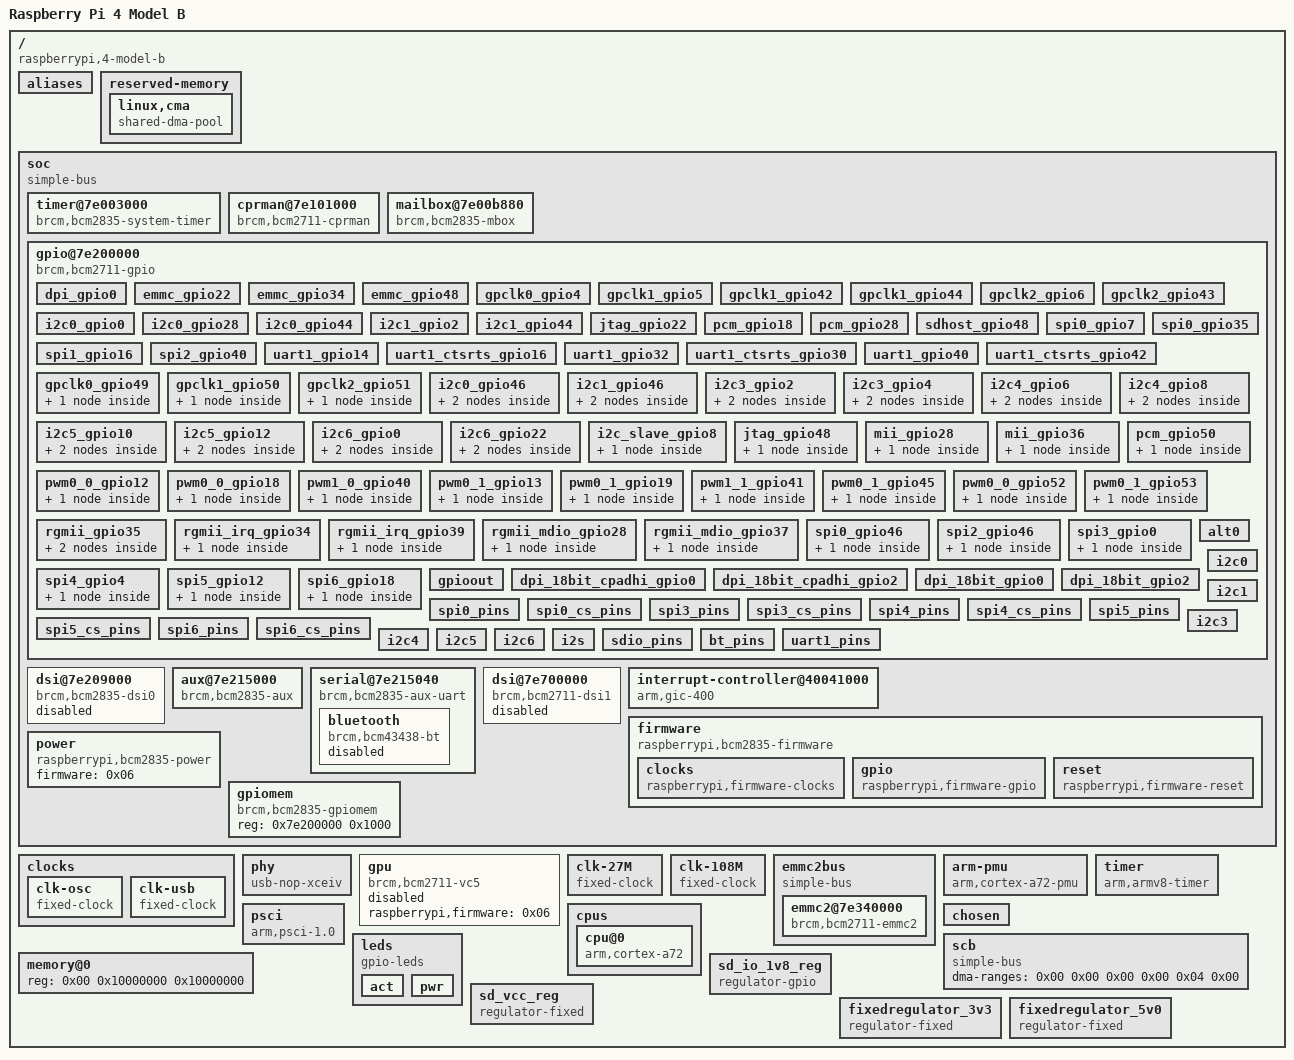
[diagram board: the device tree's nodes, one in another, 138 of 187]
/dts-v1/;

/memreserve/	0x0000000000000000 0x0000000000001000;
/ {
	compatible = "raspberrypi,4-model-b\0brcm,bcm2711";
	model = "Raspberry Pi 4 Model B";
	#address-cells = <0x02>;
	#size-cells = <0x01>;
	interrupt-parent = <0x01>;

	aliases {
		serial0 = "/soc/serial@7e215040";
		emmc2bus = "/emmc2bus";
		aux = "/soc/aux@7e215000";
		soc = "/soc";
		gpio = "/soc/gpio@7e200000";
		uart1 = "/soc/serial@7e215040";
		leds = "/leds";
	};

	reserved-memory {
		#address-cells = <0x02>;
		#size-cells = <0x01>;
		ranges;
		phandle = <0x41>;

		linux,cma {
			compatible = "shared-dma-pool";
			size = <0x1000000>;
			reusable;
			linux,cma-default;
			alloc-ranges = <0x00 0x10000000 0x30000000>;
			phandle = <0x42>;
		};
	};

	soc {
		compatible = "simple-bus";
		#address-cells = <0x01>;
		#size-cells = <0x01>;
		ranges = <0x7e000000 0x00 0xfe000000 0x1800000 0x7c000000 0x00 0xfc000000 0x2000000 0x40000000 0x00 0xff800000 0x800000>;
		dma-ranges = <0xd0000000 0x00 0x10000000 0x10000000>;
		phandle = <0x45>;

		timer@7e003000 {
			compatible = "brcm,bcm2835-system-timer";
			reg = <0x7e003000 0x1000>;
			interrupts = <0x00 0x40 0x04 0x00 0x41 0x04 0x00 0x42 0x04 0x00 0x43 0x04>;
			clock-frequency = <0xf4240>;
			phandle = <0x46>;
		};

		cprman@7e101000 {
			compatible = "brcm,bcm2711-cprman";
			#clock-cells = <0x01>;
			reg = <0x7e101000 0x2000>;
			clocks = <0x03 0x04 0x00 0x04 0x01 0x04 0x02 0x05 0x00 0x05 0x01 0x05 0x02>;
			firmware = <0x06>;
			phandle = <0x07>;
		};

		mailbox@7e00b880 {
			compatible = "brcm,bcm2835-mbox";
			reg = <0x7e00b880 0x40>;
			interrupts = <0x00 0x21 0x04>;
			#mbox-cells = <0x00>;
			phandle = <0x22>;
		};

		gpio@7e200000 {
			compatible = "brcm,bcm2711-gpio";
			reg = <0x7e200000 0xb4>;
			interrupts = <0x00 0x71 0x04 0x00 0x72 0x04>;
			gpio-controller;
			#gpio-cells = <0x02>;
			interrupt-controller;
			#interrupt-cells = <0x02>;
			pinctrl-names = "default";
			gpio-line-names = "ID_SDA\0ID_SCL\0SDA1\0SCL1\0GPIO_GCLK\0GPIO5\0GPIO6\0SPI_CE1_N\0SPI_CE0_N\0SPI_MISO\0SPI_MOSI\0SPI_SCLK\0GPIO12\0GPIO13\0TXD1\0RXD1\0GPIO16\0GPIO17\0GPIO18\0GPIO19\0GPIO20\0GPIO21\0GPIO22\0GPIO23\0GPIO24\0GPIO25\0GPIO26\0GPIO27\0RGMII_MDIO\0RGMIO_MDC\0CTS0\0RTS0\0TXD0\0RXD0\0SD1_CLK\0SD1_CMD\0SD1_DATA0\0SD1_DATA1\0SD1_DATA2\0SD1_DATA3\0PWM0_MISO\0PWM1_MOSI\0STATUS_LED_G_CLK\0SPIFLASH_CE_N\0SDA0\0SCL0\0RGMII_RXCLK\0RGMII_RXCTL\0RGMII_RXD0\0RGMII_RXD1\0RGMII_RXD2\0RGMII_RXD3\0RGMII_TXCLK\0RGMII_TXCTL\0RGMII_TXD0\0RGMII_TXD1\0RGMII_TXD2\0RGMII_TXD3";
			phandle = <0x0f>;

			dpi_gpio0 {
				brcm,pins = <0x00 0x01 0x02 0x03 0x04 0x05 0x06 0x07 0x08 0x09 0x0a 0x0b 0x0c 0x0d 0x0e 0x0f 0x10 0x11 0x12 0x13 0x14 0x15 0x16 0x17 0x18 0x19 0x1a 0x1b>;
				brcm,function = <0x06>;
				phandle = <0x48>;
			};

			emmc_gpio22 {
				brcm,pins = <0x16 0x17 0x18 0x19 0x1a 0x1b>;
				brcm,function = <0x07>;
				phandle = <0x49>;
			};

			emmc_gpio34 {
				brcm,pins = <0x22 0x23 0x24 0x25 0x26 0x27>;
				brcm,function = <0x07>;
				brcm,pull = <0x00 0x02 0x02 0x02 0x02 0x02>;
				phandle = <0x4a>;
			};

			emmc_gpio48 {
				brcm,pins = <0x30 0x31 0x32 0x33 0x34 0x35>;
				brcm,function = <0x07>;
				phandle = <0x24>;
			};

			gpclk0_gpio4 {
				brcm,pins = <0x04>;
				brcm,function = <0x04>;
				phandle = <0x4b>;
			};

			gpclk1_gpio5 {
				brcm,pins = <0x05>;
				brcm,function = <0x04>;
				phandle = <0x4c>;
			};

			gpclk1_gpio42 {
				brcm,pins = <0x2a>;
				brcm,function = <0x04>;
				phandle = <0x4d>;
			};

			gpclk1_gpio44 {
				brcm,pins = <0x2c>;
				brcm,function = <0x04>;
				phandle = <0x4e>;
			};

			gpclk2_gpio6 {
				brcm,pins = <0x06>;
				brcm,function = <0x04>;
				phandle = <0x4f>;
			};

			gpclk2_gpio43 {
				brcm,pins = <0x2b>;
				brcm,function = <0x04>;
				brcm,pull = <0x00>;
				phandle = <0x50>;
			};

			i2c0_gpio0 {
				brcm,pins = <0x00 0x01>;
				brcm,function = <0x04>;
				phandle = <0x11>;
			};

			i2c0_gpio28 {
				brcm,pins = <0x1c 0x1d>;
				brcm,function = <0x04>;
				phandle = <0x51>;
			};

			i2c0_gpio44 {
				brcm,pins = <0x2c 0x2d>;
				brcm,function = <0x05>;
				phandle = <0x12>;
			};

			i2c1_gpio2 {
				brcm,pins = <0x02 0x03>;
				brcm,function = <0x04>;
				phandle = <0x52>;
			};

			i2c1_gpio44 {
				brcm,pins = <0x2c 0x2d>;
				brcm,function = <0x06>;
				phandle = <0x53>;
			};

			jtag_gpio22 {
				brcm,pins = <0x16 0x17 0x18 0x19 0x1a 0x1b>;
				brcm,function = <0x03>;
				phandle = <0x54>;
			};

			pcm_gpio18 {
				brcm,pins = <0x12 0x13 0x14 0x15>;
				brcm,function = <0x04>;
				phandle = <0x55>;
			};

			pcm_gpio28 {
				brcm,pins = <0x1c 0x1d 0x1e 0x1f>;
				brcm,function = <0x06>;
				phandle = <0x56>;
			};

			sdhost_gpio48 {
				brcm,pins = <0x30 0x31 0x32 0x33 0x34 0x35>;
				brcm,function = <0x04>;
				phandle = <0x57>;
			};

			spi0_gpio7 {
				brcm,pins = <0x07 0x08 0x09 0x0a 0x0b>;
				brcm,function = <0x04>;
				phandle = <0x58>;
			};

			spi0_gpio35 {
				brcm,pins = <0x23 0x24 0x25 0x26 0x27>;
				brcm,function = <0x04>;
				phandle = <0x59>;
			};

			spi1_gpio16 {
				brcm,pins = <0x10 0x11 0x12 0x13 0x14 0x15>;
				brcm,function = <0x03>;
				phandle = <0x5a>;
			};

			spi2_gpio40 {
				brcm,pins = <0x28 0x29 0x2a 0x2b 0x2c 0x2d>;
				brcm,function = <0x03>;
				phandle = <0x5b>;
			};

			uart1_gpio14 {
				brcm,pins = <0x0e 0x0f>;
				brcm,function = <0x02>;
				phandle = <0x62>;
			};

			uart1_ctsrts_gpio16 {
				brcm,pins = <0x10 0x11>;
				brcm,function = <0x02>;
				phandle = <0x63>;
			};

			uart1_gpio32 {
				brcm,pins = <0x20 0x21>;
				brcm,function = <0x02>;
				phandle = <0x64>;
			};

			uart1_ctsrts_gpio30 {
				brcm,pins = <0x1e 0x1f>;
				brcm,function = <0x02>;
				phandle = <0x65>;
			};

			uart1_gpio40 {
				brcm,pins = <0x28 0x29>;
				brcm,function = <0x02>;
				phandle = <0x66>;
			};

			uart1_ctsrts_gpio42 {
				brcm,pins = <0x2a 0x2b>;
				brcm,function = <0x02>;
				phandle = <0x67>;
			};

			gpclk0_gpio49 {
				phandle = <0x68>;

				pin-gpclk {
					pins = "gpio49";
					function = "alt1";
					bias-disable;
				};
			};

			gpclk1_gpio50 {
				phandle = <0x69>;

				pin-gpclk {
					pins = "gpio50";
					function = "alt1";
					bias-disable;
				};
			};

			gpclk2_gpio51 {
				phandle = <0x6a>;

				pin-gpclk {
					pins = "gpio51";
					function = "alt1";
					bias-disable;
				};
			};

			i2c0_gpio46 {
				phandle = <0x6b>;

				pin-sda {
					function = "alt0";
					pins = "gpio46";
					bias-pull-up;
				};

				pin-scl {
					function = "alt0";
					pins = "gpio47";
					bias-disable;
				};
			};

			i2c1_gpio46 {
				phandle = <0x6c>;

				pin-sda {
					function = "alt1";
					pins = "gpio46";
					bias-pull-up;
				};

				pin-scl {
					function = "alt1";
					pins = "gpio47";
					bias-disable;
				};
			};

			i2c3_gpio2 {
				phandle = <0x6d>;

				pin-sda {
					function = "alt5";
					pins = "gpio2";
					bias-pull-up;
				};

				pin-scl {
					function = "alt5";
					pins = "gpio3";
					bias-disable;
				};
			};

			i2c3_gpio4 {
				phandle = <0x6e>;

				pin-sda {
					function = "alt5";
					pins = "gpio4";
					bias-pull-up;
				};

				pin-scl {
					function = "alt5";
					pins = "gpio5";
					bias-disable;
				};
			};

			i2c4_gpio6 {
				phandle = <0x6f>;

				pin-sda {
					function = "alt5";
					pins = "gpio6";
					bias-pull-up;
				};

				pin-scl {
					function = "alt5";
					pins = "gpio7";
					bias-disable;
				};
			};

			i2c4_gpio8 {
				phandle = <0x70>;

				pin-sda {
					function = "alt5";
					pins = "gpio8";
					bias-pull-up;
				};

				pin-scl {
					function = "alt5";
					pins = "gpio9";
					bias-disable;
				};
			};

			i2c5_gpio10 {
				phandle = <0x71>;

				pin-sda {
					function = "alt5";
					pins = "gpio10";
					bias-pull-up;
				};

				pin-scl {
					function = "alt5";
					pins = "gpio11";
					bias-disable;
				};
			};

			i2c5_gpio12 {
				phandle = <0x72>;

				pin-sda {
					function = "alt5";
					pins = "gpio12";
					bias-pull-up;
				};

				pin-scl {
					function = "alt5";
					pins = "gpio13";
					bias-disable;
				};
			};

			i2c6_gpio0 {
				phandle = <0x73>;

				pin-sda {
					function = "alt5";
					pins = "gpio0";
					bias-pull-up;
				};

				pin-scl {
					function = "alt5";
					pins = "gpio1";
					bias-disable;
				};
			};

			i2c6_gpio22 {
				phandle = <0x74>;

				pin-sda {
					function = "alt5";
					pins = "gpio22";
					bias-pull-up;
				};

				pin-scl {
					function = "alt5";
					pins = "gpio23";
					bias-disable;
				};
			};

			i2c_slave_gpio8 {
				phandle = <0x75>;

				pins-i2c-slave {
					pins = "gpio8\0gpio9\0gpio10\0gpio11";
					function = "alt3";
				};
			};

			jtag_gpio48 {
				phandle = <0x76>;

				pins-jtag {
					pins = "gpio48\0gpio49\0gpio50\0gpio51\0gpio52\0gpio53";
					function = "alt4";
				};
			};

			mii_gpio28 {
				phandle = <0x77>;

				pins-mii {
					pins = "gpio28\0gpio29\0gpio30\0gpio31";
					function = "alt4";
				};
			};

			mii_gpio36 {
				phandle = <0x78>;

				pins-mii {
					pins = "gpio36\0gpio37\0gpio38\0gpio39";
					function = "alt5";
				};
			};

			pcm_gpio50 {
				phandle = <0x79>;

				pins-pcm {
					pins = "gpio50\0gpio51\0gpio52\0gpio53";
					function = "alt2";
				};
			};

			pwm0_0_gpio12 {
				phandle = <0x7a>;

				pin-pwm {
					pins = "gpio12";
					function = "alt0";
					bias-disable;
				};
			};

			pwm0_0_gpio18 {
				phandle = <0x7b>;

				pin-pwm {
					pins = "gpio18";
					function = "alt5";
					bias-disable;
				};
			};

			pwm1_0_gpio40 {
				phandle = <0x1a>;

				pin-pwm {
					pins = "gpio40";
					function = "alt0";
					bias-disable;
				};
			};

			pwm0_1_gpio13 {
				phandle = <0x7c>;

				pin-pwm {
					pins = "gpio13";
					function = "alt0";
					bias-disable;
				};
			};

			pwm0_1_gpio19 {
				phandle = <0x7d>;

				pin-pwm {
					pins = "gpio19";
					function = "alt5";
					bias-disable;
				};
			};

			pwm1_1_gpio41 {
				phandle = <0x1b>;

				pin-pwm {
					pins = "gpio41";
					function = "alt0";
					bias-disable;
				};
			};

			pwm0_1_gpio45 {
				phandle = <0x7e>;

				pin-pwm {
					pins = "gpio45";
					function = "alt0";
					bias-disable;
				};
			};

			pwm0_0_gpio52 {
				phandle = <0x7f>;

				pin-pwm {
					pins = "gpio52";
					function = "alt1";
					bias-disable;
				};
			};

			pwm0_1_gpio53 {
				phandle = <0x80>;

				pin-pwm {
					pins = "gpio53";
					function = "alt1";
					bias-disable;
				};
			};

			rgmii_gpio35 {
				phandle = <0x81>;

				pin-start-stop {
					pins = "gpio35";
					function = "alt4";
				};

				pin-rx-ok {
					pins = "gpio36";
					function = "alt4";
				};
			};

			rgmii_irq_gpio34 {
				phandle = <0x82>;

				pin-irq {
					pins = "gpio34";
					function = "alt5";
				};
			};

			rgmii_irq_gpio39 {
				phandle = <0x83>;

				pin-irq {
					pins = "gpio39";
					function = "alt4";
				};
			};

			rgmii_mdio_gpio28 {
				phandle = <0x84>;

				pins-mdio {
					pins = "gpio28\0gpio29";
					function = "alt5";
				};
			};

			rgmii_mdio_gpio37 {
				phandle = <0x85>;

				pins-mdio {
					pins = "gpio37\0gpio38";
					function = "alt4";
				};
			};

			spi0_gpio46 {
				phandle = <0x86>;

				pins-spi {
					pins = "gpio46\0gpio47\0gpio48\0gpio49";
					function = "alt2";
				};
			};

			spi2_gpio46 {
				phandle = <0x87>;

				pins-spi {
					pins = "gpio46\0gpio47\0gpio48\0gpio49\0gpio50";
					function = "alt5";
				};
			};

			spi3_gpio0 {
				phandle = <0x88>;

				pins-spi {
					pins = "gpio0\0gpio1\0gpio2\0gpio3";
					function = "alt3";
				};
			};

			spi4_gpio4 {
				phandle = <0x89>;

				pins-spi {
					pins = "gpio4\0gpio5\0gpio6\0gpio7";
					function = "alt3";
				};
			};

			spi5_gpio12 {
				phandle = <0x8a>;

				pins-spi {
					pins = "gpio12\0gpio13\0gpio14\0gpio15";
					function = "alt3";
				};
			};

			spi6_gpio18 {
				phandle = <0x8b>;

				pins-spi {
					pins = "gpio18\0gpio19\0gpio20\0gpio21";
					function = "alt3";
				};
			};

			gpioout {
				brcm,pins = <0x06>;
				brcm,function = <0x01>;
				phandle = <0x94>;
			};

			alt0 {
				brcm,pins = <0x04 0x05 0x07 0x08 0x09 0x0a 0x0b>;
				brcm,function = <0x04>;
				phandle = <0x95>;
			};

			dpi_18bit_cpadhi_gpio0 {
				brcm,pins = <0x00 0x01 0x02 0x03 0x04 0x05 0x06 0x07 0x08 0x09 0x0c 0x0d 0x0e 0x0f 0x10 0x11 0x14 0x15 0x16 0x17 0x18 0x19>;
				brcm,function = <0x06>;
				brcm,pull = <0x00>;
				phandle = <0x96>;
			};

			dpi_18bit_cpadhi_gpio2 {
				brcm,pins = <0x02 0x03 0x04 0x05 0x06 0x07 0x08 0x09 0x0c 0x0d 0x0e 0x0f 0x10 0x11 0x14 0x15 0x16 0x17 0x18 0x19>;
				brcm,function = <0x06>;
				phandle = <0x97>;
			};

			dpi_18bit_gpio0 {
				brcm,pins = <0x00 0x01 0x02 0x03 0x04 0x05 0x06 0x07 0x08 0x09 0x0a 0x0b 0x0c 0x0d 0x0e 0x0f 0x10 0x11 0x12 0x13 0x14 0x15>;
				brcm,function = <0x06>;
				phandle = <0x98>;
			};

			dpi_18bit_gpio2 {
				brcm,pins = <0x02 0x03 0x04 0x05 0x06 0x07 0x08 0x09 0x0a 0x0b 0x0c 0x0d 0x0e 0x0f 0x10 0x11 0x12 0x13 0x14 0x15>;
				brcm,function = <0x06>;
				phandle = <0x99>;
			};

			spi0_pins {
				brcm,pins = <0x09 0x0a 0x0b>;
				brcm,function = <0x04>;
				phandle = <0x0d>;
			};

			spi0_cs_pins {
				brcm,pins = <0x08 0x07>;
				brcm,function = <0x01>;
				phandle = <0x0e>;
			};

			spi3_pins {
				brcm,pins = <0x01 0x02 0x03>;
				brcm,function = <0x07>;
				phandle = <0x9a>;
			};

			spi3_cs_pins {
				brcm,pins = <0x00 0x18>;
				brcm,function = <0x01>;
				phandle = <0x9b>;
			};

			spi4_pins {
				brcm,pins = <0x05 0x06 0x07>;
				brcm,function = <0x07>;
				phandle = <0x9c>;
			};

			spi4_cs_pins {
				brcm,pins = <0x04 0x19>;
				brcm,function = <0x01>;
				phandle = <0x9d>;
			};

			spi5_pins {
				brcm,pins = <0x0d 0x0e 0x0f>;
				brcm,function = <0x07>;
				phandle = <0x9e>;
			};

			spi5_cs_pins {
				brcm,pins = <0x0c 0x1a>;
				brcm,function = <0x01>;
				phandle = <0x9f>;
			};

			spi6_pins {
				brcm,pins = <0x13 0x14 0x15>;
				brcm,function = <0x07>;
				phandle = <0xa0>;
			};

			spi6_cs_pins {
				brcm,pins = <0x12 0x1b>;
				brcm,function = <0x01>;
				phandle = <0xa1>;
			};

			i2c0 {
				brcm,pins = <0x00 0x01>;
				brcm,function = <0x04>;
				brcm,pull = <0x02>;
				phandle = <0xa2>;
			};

			i2c1 {
				brcm,pins = <0x02 0x03>;
				brcm,function = <0x04>;
				brcm,pull = <0x02>;
				phandle = <0x17>;
			};

			i2c3 {
				brcm,pins = <0x04 0x05>;
				brcm,function = <0x02>;
				brcm,pull = <0x02>;
				phandle = <0xa3>;
			};

			i2c4 {
				brcm,pins = <0x08 0x09>;
				brcm,function = <0x02>;
				brcm,pull = <0x02>;
				phandle = <0xa4>;
			};

			i2c5 {
				brcm,pins = <0x0c 0x0d>;
				brcm,function = <0x02>;
				brcm,pull = <0x02>;
				phandle = <0xa5>;
			};

			i2c6 {
				brcm,pins = <0x16 0x17>;
				brcm,function = <0x02>;
				brcm,pull = <0x02>;
				phandle = <0xa6>;
			};

			i2s {
				brcm,pins = <0x12 0x13 0x14 0x15>;
				brcm,function = <0x04>;
				phandle = <0x0c>;
			};

			sdio_pins {
				brcm,pins = <0x22 0x23 0x24 0x25 0x26 0x27>;
				brcm,function = <0x07>;
				brcm,pull = <0x00 0x02 0x02 0x02 0x02 0x02>;
				phandle = <0x25>;
			};

			bt_pins {
				brcm,pins = [2d 00];
				brcm,function = <0x00>;
				brcm,pull = <0x02>;
				phandle = <0x09>;
			};

			uart1_pins {
				brcm,pins;
				brcm,function;
				brcm,pull;
				phandle = <0x15>;
			};
		};

		dsi@7e209000 {
			compatible = "brcm,bcm2835-dsi0";
			reg = <0x7e209000 0x78>;
			interrupts = <0x00 0x64 0x04>;
			#address-cells = <0x01>;
			#size-cells = <0x00>;
			#clock-cells = <0x01>;
			clocks = <0x07 0x20 0x07 0x2f 0x07 0x31>;
			clock-names = "phy\0escape\0pixel";
			clock-output-names = "dsi0_byte\0dsi0_ddr2\0dsi0_ddr";
			status = "disabled";
			power-domains = <0x13 0x11>;
			phandle = <0x04>;
		};

		aux@7e215000 {
			compatible = "brcm,bcm2835-aux";
			#clock-cells = <0x01>;
			reg = <0x7e215000 0x08>;
			clocks = <0x07 0x14>;
			phandle = <0x14>;
		};

		serial@7e215040 {
			compatible = "brcm,bcm2835-aux-uart";
			reg = <0x7e215040 0x40>;
			interrupts = <0x00 0x5d 0x04>;
			clocks = <0x14 0x00>;
			status = "okay";
			pinctrl-names = "default";
			pinctrl-0 = <0x15>;
			skip-init;
			phandle = <0x31>;

			bluetooth {
				compatible = "brcm,bcm43438-bt";
				max-speed = <0x70800>;
				shutdown-gpios = <0x0a 0x00 0x00>;
				status = "disabled";
				phandle = <0xb0>;
			};
		};

		dsi@7e700000 {
			compatible = "brcm,bcm2711-dsi1";
			reg = <0x7e700000 0x8c>;
			interrupts = <0x00 0x6c 0x04>;
			#address-cells = <0x01>;
			#size-cells = <0x00>;
			#clock-cells = <0x01>;
			clocks = <0x07 0x23 0x07 0x30 0x07 0x32>;
			clock-names = "phy\0escape\0pixel";
			clock-output-names = "dsi1_byte\0dsi1_ddr2\0dsi1_ddr";
			status = "disabled";
			power-domains = <0x13 0x12>;
			phandle = <0x05>;
		};

		interrupt-controller@40041000 {
			interrupt-controller;
			#interrupt-cells = <0x03>;
			compatible = "arm,gic-400";
			reg = <0x40041000 0x1000 0x40042000 0x2000 0x40044000 0x2000 0x40046000 0x2000>;
			interrupts = <0x01 0x09 0xf04>;
			phandle = <0x01>;
		};

		firmware {
			compatible = "raspberrypi,bcm2835-firmware\0simple-mfd";
			#address-cells = <0x01>;
			#size-cells = <0x01>;
			mboxes = <0x22>;
			dma-ranges;
			phandle = <0x06>;

			clocks {
				compatible = "raspberrypi,firmware-clocks";
				#clock-cells = <0x01>;
				phandle = <0x16>;
			};

			gpio {
				compatible = "raspberrypi,firmware-gpio";
				gpio-controller;
				#gpio-cells = <0x02>;
				gpio-line-names = "BT_ON\0WL_ON\0PWR_LED_OFF\0GLOBAL_RESET\0VDD_SD_IO_SEL\0CAM_GPIO\0SD_PWR_ON\0SD_OC_N";
				status = "okay";
				phandle = <0x0a>;
			};

			reset {
				compatible = "raspberrypi,firmware-reset";
				#reset-cells = <0x01>;
				phandle = <0x2d>;
			};
		};

		power {
			compatible = "raspberrypi,bcm2835-power";
			firmware = <0x06>;
			#power-domain-cells = <0x01>;
			phandle = <0x13>;
		};

		gpiomem {
			compatible = "brcm,bcm2835-gpiomem";
			reg = <0x7e200000 0x1000>;
		};
	};

	clocks {

		clk-osc {
			compatible = "fixed-clock";
			#clock-cells = <0x00>;
			clock-output-names = "osc";
			clock-frequency = <0x337f980>;
			phandle = <0x03>;
		};

		clk-usb {
			compatible = "fixed-clock";
			#clock-cells = <0x00>;
			clock-output-names = "otg";
			clock-frequency = <0x1c9c3800>;
			phandle = <0x18>;
		};
	};

	phy {
		compatible = "usb-nop-xceiv";
		#phy-cells = <0x00>;
		phandle = <0x19>;
	};

	gpu {
		compatible = "brcm,bcm2711-vc5";
		status = "disabled";
		raspberrypi,firmware = <0x06>;
		phandle = <0xd5>;
	};

	clk-27M {
		#clock-cells = <0x00>;
		compatible = "fixed-clock";
		clock-frequency = <0x19bfcc0>;
		clock-output-names = "27MHz-clock";
		phandle = <0x1e>;
	};

	clk-108M {
		#clock-cells = <0x00>;
		compatible = "fixed-clock";
		clock-frequency = <0x66ff300>;
		clock-output-names = "108MHz-clock";
		phandle = <0x1c>;
	};

	emmc2bus {
		compatible = "simple-bus";
		#address-cells = <0x02>;
		#size-cells = <0x01>;
		ranges = <0x00 0x7e000000 0x00 0xfe000000 0x1800000>;
		dma-ranges = <0x00 0xc0000000 0x00 0x00 0x40000000>;
		phandle = <0xd6>;
		
		emmc2@7e340000 {
			compatible = "brcm,bcm2711-emmc2";
			reg = <0x00 0x7e340000 0x100>;
			interrupts = <0x00 0x7e 0x04>;
			clocks = <0x07 0x33>;
			status = "okay";
			vqmmc-supply = <0x26>;
			vmmc-supply = <0x27>;
			broken-cd;
			mmc-ddr-3_3v;
			phandle = <0x3f>;
		};
	};

	arm-pmu {
		compatible = "arm,cortex-a72-pmu\0arm,armv8-pmuv3";
		interrupts = <0x00 0x10 0x04 0x00 0x11 0x04 0x00 0x12 0x04 0x00 0x13 0x04>;
		interrupt-affinity = <0x28 0x29 0x2a 0x2b>;
	};

	timer {
		arm,cpu-registers-not-fw-configured;
		compatible = "arm,armv8-timer";
		interrupts = <0x01 0x0d 0xf08 0x01 0x0e 0xf08 0x01 0x0b 0xf08 0x01 0x0a 0xf08>;
	};
	
	psci {
		compatible = "arm,psci-1.0";
		method = "smc";
		cpu_off = <0x84000002>;
		cpu_on = <0xc4000003>;
		cpu_suspend = <0xc4000001>;
		status = "okay";
	};
	
	cpus {
		#address-cells = <0x01>;
		#size-cells = <0x00>;

		cpu@0 {
			device_type = "cpu";
			compatible = "arm,cortex-a72";
			reg = <0x00>;
			enable-method = "psci";
		};
	};

	chosen {
		bootargs = "nosmp maxcpus=1 coherent_pool=1M 8250.nr_uarts=1 root=/dev/mmcblk0p2 rw rootwait debug loglevel=7 console=tty1 console=ttyS0,115200 earlycon=uart8250,mmio32,0xfe215040";
	};

	scb {
		compatible = "simple-bus";
		#address-cells = <0x02>;
		#size-cells = <0x02>;
		ranges = <0x00 0x7c000000 0x00 0xfc000000 0x00 0x3800000 0x00 0x40000000 0x00 0xff800000 0x00 0x800000 0x06 0x00 0x06 0x00 0x00 0x40000000 0x00 0x00 0x00 0x00 0x00 0xfc000000>;
		dma-ranges = <0x00 0x00 0x00 0x00 0x04 0x00>;
		phandle = <0xd8>;
	};

	leds {
		compatible = "gpio-leds";
		phandle = <0xdc>;

		act {
			label = "led0";
			default-state = "keep";
			linux,default-trigger = "mmc0";
			gpios = <0x0f 0x2a 0x00>;
			phandle = <0x3d>;
		};

		pwr {
			label = "led1";
			gpios = <0x0a 0x02 0x01>;
			default-state = "keep";
			linux,default-trigger = "default-on";
			phandle = <0x3e>;
		};
	};

	memory@0 {
		device_type = "memory";
		reg = <0x00 0x10000000 0x10000000>;
	};

	sd_io_1v8_reg {
		compatible = "regulator-gpio";
		regulator-name = "vdd-sd-io";
		regulator-min-microvolt = <0x1b7740>;
		regulator-max-microvolt = <0x325aa0>;
		regulator-boot-on;
		regulator-always-on;
		regulator-settling-time-us = <0x1388>;
		gpios = <0x0a 0x04 0x00>;
		states = <0x1b7740 0x01 0x325aa0 0x00>;
		status = "okay";
		phandle = <0x26>;
	};

	sd_vcc_reg {
		compatible = "regulator-fixed";
		regulator-name = "vcc-sd";
		regulator-min-microvolt = <0x325aa0>;
		regulator-max-microvolt = <0x325aa0>;
		regulator-boot-on;
		enable-active-high;
		gpio = <0x0a 0x06 0x00>;
		phandle = <0x27>;
	};

	__overrides__ {
		cam0-pwdn-ctrl;
		cam0-pwdn;
		cam0-led-ctrl;
		cam0-led;
		krnbt = "\0\0\0/status";
		krnbt_baudrate = "\0\0\0/max-speed:0";
		cache_line_size;
		uart0 = "\0\0\0status";
		uart1 = [00 00 01 73 74 61 74 75 73 00];
		i2s = [00 00 02 73 74 61 74 75 73 00];
		spi = [00 00 03 73 74 61 74 75 73 00];
		i2c0 = [00 00 00 10 73 74 61 74 75 73 00 00 00 00 34 73 74 61 74 75 73 00];
		i2c1 = [00 00 05 73 74 61 74 75 73 00];
		i2c0_baudrate = [00 00 00 10 63 6c 6f 63 6b 2d 66 72 65 71 75 65 6e 63 79 3a 30 00];
		i2c1_baudrate = [00 00 05 63 6c 6f 63 6b 2d 66 72 65 71 75 65 6e 63 79 3a 30 00];
		watchdog = "\0\0\astatus";
		random = "\0\0\08status";
		sd_overclock = "\0\0\09brcm,overclock-50:0";
		sd_force_pio = "\0\0\09brcm,force-pio?";
		sd_pio_limit = "\0\0\09brcm,pio-limit:0";
		sd_debug = "\0\0\09brcm,debug";
		sdio_overclock = "\0\0\0:brcm,overclock-50:0\0\0\0\0;brcm,overclock-50:0";
		arm_freq;
		act_led_gpio = "\0\0\0=gpios:4";
		act_led_activelow = "\0\0\0=gpios:8";
		act_led_trigger = "\0\0\0=linux,default-trigger";
		pwr_led_gpio = "\0\0\0>gpios:4";
		pwr_led_activelow = "\0\0\0>gpios:8";
		pwr_led_trigger = "\0\0\0>linux,default-trigger";
		eth_led0 = "\0\0\0.led-modes:0";
		eth_led1 = "\0\0\0.led-modes:4";
		sd_poll_once = "\0\0\0?non-removable?";
		spi_dma4 = <0x33 0x646d6173 0x3a303d00 0x40 0x33 0x646d6173 0x3a383d00 0x40>;
	};

	fixedregulator_3v3 {
		compatible = "regulator-fixed";
		regulator-always-on;
		regulator-max-microvolt = <0x325aa0>;
		regulator-min-microvolt = <0x325aa0>;
		regulator-name = "3v3";
		phandle = <0xdd>;
	};

	fixedregulator_5v0 {
		compatible = "regulator-fixed";
		regulator-always-on;
		regulator-max-microvolt = <0x4c4b40>;
		regulator-min-microvolt = <0x4c4b40>;
		regulator-name = "5v0";
		phandle = <0xde>;
	};

	__symbols__ {
		rmem = "/reserved-memory";
		cma = "/reserved-memory/linux,cma";
		soc = "/soc";
		system_timer = "/soc/timer@7e003000";
		clocks = "/soc/cprman@7e101000";
		mailbox = "/soc/mailbox@7e00b880";
		gpio = "/soc/gpio@7e200000";
		dpi_gpio0 = "/soc/gpio@7e200000/dpi_gpio0";
		emmc_gpio22 = "/soc/gpio@7e200000/emmc_gpio22";
		emmc_gpio34 = "/soc/gpio@7e200000/emmc_gpio34";
		emmc_gpio48 = "/soc/gpio@7e200000/emmc_gpio48";
		gpclk0_gpio4 = "/soc/gpio@7e200000/gpclk0_gpio4";
		gpclk1_gpio5 = "/soc/gpio@7e200000/gpclk1_gpio5";
		gpclk1_gpio42 = "/soc/gpio@7e200000/gpclk1_gpio42";
		gpclk1_gpio44 = "/soc/gpio@7e200000/gpclk1_gpio44";
		gpclk2_gpio6 = "/soc/gpio@7e200000/gpclk2_gpio6";
		gpclk2_gpio43 = "/soc/gpio@7e200000/gpclk2_gpio43";
		i2c0_gpio0 = "/soc/gpio@7e200000/i2c0_gpio0";
		i2c0_gpio28 = "/soc/gpio@7e200000/i2c0_gpio28";
		i2c0_gpio44 = "/soc/gpio@7e200000/i2c0_gpio44";
		i2c1_gpio2 = "/soc/gpio@7e200000/i2c1_gpio2";
		i2c1_gpio44 = "/soc/gpio@7e200000/i2c1_gpio44";
		jtag_gpio22 = "/soc/gpio@7e200000/jtag_gpio22";
		pcm_gpio18 = "/soc/gpio@7e200000/pcm_gpio18";
		pcm_gpio28 = "/soc/gpio@7e200000/pcm_gpio28";
		sdhost_gpio48 = "/soc/gpio@7e200000/sdhost_gpio48";
		spi0_gpio7 = "/soc/gpio@7e200000/spi0_gpio7";
		spi0_gpio35 = "/soc/gpio@7e200000/spi0_gpio35";
		spi1_gpio16 = "/soc/gpio@7e200000/spi1_gpio16";
		spi2_gpio40 = "/soc/gpio@7e200000/spi2_gpio40";
		uart1_gpio14 = "/soc/gpio@7e200000/uart1_gpio14";
		uart1_ctsrts_gpio16 = "/soc/gpio@7e200000/uart1_ctsrts_gpio16";
		uart1_gpio32 = "/soc/gpio@7e200000/uart1_gpio32";
		uart1_ctsrts_gpio30 = "/soc/gpio@7e200000/uart1_ctsrts_gpio30";
		uart1_gpio40 = "/soc/gpio@7e200000/uart1_gpio40";
		uart1_ctsrts_gpio42 = "/soc/gpio@7e200000/uart1_ctsrts_gpio42";
		gpclk0_gpio49 = "/soc/gpio@7e200000/gpclk0_gpio49";
		gpclk1_gpio50 = "/soc/gpio@7e200000/gpclk1_gpio50";
		gpclk2_gpio51 = "/soc/gpio@7e200000/gpclk2_gpio51";
		i2c0_gpio46 = "/soc/gpio@7e200000/i2c0_gpio46";
		i2c1_gpio46 = "/soc/gpio@7e200000/i2c1_gpio46";
		i2c3_gpio2 = "/soc/gpio@7e200000/i2c3_gpio2";
		i2c3_gpio4 = "/soc/gpio@7e200000/i2c3_gpio4";
		i2c4_gpio6 = "/soc/gpio@7e200000/i2c4_gpio6";
		i2c4_gpio8 = "/soc/gpio@7e200000/i2c4_gpio8";
		i2c5_gpio10 = "/soc/gpio@7e200000/i2c5_gpio10";
		i2c5_gpio12 = "/soc/gpio@7e200000/i2c5_gpio12";
		i2c6_gpio0 = "/soc/gpio@7e200000/i2c6_gpio0";
		i2c6_gpio22 = "/soc/gpio@7e200000/i2c6_gpio22";
		i2c_slave_gpio8 = "/soc/gpio@7e200000/i2c_slave_gpio8";
		jtag_gpio48 = "/soc/gpio@7e200000/jtag_gpio48";
		mii_gpio28 = "/soc/gpio@7e200000/mii_gpio28";
		mii_gpio36 = "/soc/gpio@7e200000/mii_gpio36";
		pcm_gpio50 = "/soc/gpio@7e200000/pcm_gpio50";
		pwm0_0_gpio12 = "/soc/gpio@7e200000/pwm0_0_gpio12";
		pwm0_0_gpio18 = "/soc/gpio@7e200000/pwm0_0_gpio18";
		pwm1_0_gpio40 = "/soc/gpio@7e200000/pwm1_0_gpio40";
		pwm0_1_gpio13 = "/soc/gpio@7e200000/pwm0_1_gpio13";
		pwm0_1_gpio19 = "/soc/gpio@7e200000/pwm0_1_gpio19";
		pwm1_1_gpio41 = "/soc/gpio@7e200000/pwm1_1_gpio41";
		pwm0_1_gpio45 = "/soc/gpio@7e200000/pwm0_1_gpio45";
		pwm0_0_gpio52 = "/soc/gpio@7e200000/pwm0_0_gpio52";
		pwm0_1_gpio53 = "/soc/gpio@7e200000/pwm0_1_gpio53";
		rgmii_gpio35 = "/soc/gpio@7e200000/rgmii_gpio35";
		rgmii_irq_gpio34 = "/soc/gpio@7e200000/rgmii_irq_gpio34";
		rgmii_irq_gpio39 = "/soc/gpio@7e200000/rgmii_irq_gpio39";
		rgmii_mdio_gpio28 = "/soc/gpio@7e200000/rgmii_mdio_gpio28";
		rgmii_mdio_gpio37 = "/soc/gpio@7e200000/rgmii_mdio_gpio37";
		spi0_gpio46 = "/soc/gpio@7e200000/spi0_gpio46";
		spi2_gpio46 = "/soc/gpio@7e200000/spi2_gpio46";
		spi3_gpio0 = "/soc/gpio@7e200000/spi3_gpio0";
		spi4_gpio4 = "/soc/gpio@7e200000/spi4_gpio4";
		spi5_gpio12 = "/soc/gpio@7e200000/spi5_gpio12";
		spi6_gpio18 = "/soc/gpio@7e200000/spi6_gpio18";
		gpioout = "/soc/gpio@7e200000/gpioout";
		alt0 = "/soc/gpio@7e200000/alt0";
		dpi_18bit_cpadhi_gpio0 = "/soc/gpio@7e200000/dpi_18bit_cpadhi_gpio0";
		dpi_18bit_cpadhi_gpio2 = "/soc/gpio@7e200000/dpi_18bit_cpadhi_gpio2";
		dpi_18bit_gpio0 = "/soc/gpio@7e200000/dpi_18bit_gpio0";
		dpi_18bit_gpio2 = "/soc/gpio@7e200000/dpi_18bit_gpio2";
		spi0_pins = "/soc/gpio@7e200000/spi0_pins";
		spi0_cs_pins = "/soc/gpio@7e200000/spi0_cs_pins";
		spi3_pins = "/soc/gpio@7e200000/spi3_pins";
		spi3_cs_pins = "/soc/gpio@7e200000/spi3_cs_pins";
		spi4_pins = "/soc/gpio@7e200000/spi4_pins";
		spi4_cs_pins = "/soc/gpio@7e200000/spi4_cs_pins";
		spi5_pins = "/soc/gpio@7e200000/spi5_pins";
		spi5_cs_pins = "/soc/gpio@7e200000/spi5_cs_pins";
		spi6_pins = "/soc/gpio@7e200000/spi6_pins";
		spi6_cs_pins = "/soc/gpio@7e200000/spi6_cs_pins";
		i2c0_pins = "/soc/gpio@7e200000/i2c0";
		i2c1_pins = "/soc/gpio@7e200000/i2c1";
		i2c3_pins = "/soc/gpio@7e200000/i2c3";
		i2c4_pins = "/soc/gpio@7e200000/i2c4";
		i2c5_pins = "/soc/gpio@7e200000/i2c5";
		i2c6_pins = "/soc/gpio@7e200000/i2c6";
		i2s_pins = "/soc/gpio@7e200000/i2s";
		sdio_pins = "/soc/gpio@7e200000/sdio_pins";
		bt_pins = "/soc/gpio@7e200000/bt_pins";
		uart1_pins = "/soc/gpio@7e200000/uart1_pins";
		dsi0 = "/soc/dsi@7e209000";
		aux = "/soc/aux@7e215000";
		uart1 = "/soc/serial@7e215040";
		minibt = "/soc/serial@7e215040/bluetooth";
		dsi1 = "/soc/dsi@7e700000";
		gicv2 = "/soc/interrupt-controller@40041000";
		firmware = "/soc/firmware";
		firmware_clocks = "/soc/firmware/clocks";
		expgpio = "/soc/firmware/gpio";
		reset = "/soc/firmware/reset";
		power = "/soc/power";
		clk_osc = "/clocks/clk-osc";
		clk_usb = "/clocks/clk-usb";
		usbphy = "/phy";
		vc4 = "/gpu";
		clk_27MHz = "/clk-27M";
		clk_108MHz = "/clk-108M";
		emmc2bus = "/emmc2bus";
		cpus = "/cpus";
		cpu0 = "/cpus/cpu@0";
		scb = "/scb";
		leds = "/leds";
		act_led = "/leds/act";
		pwr_led = "/leds/pwr";
		sd_io_1v8_reg = "/sd_io_1v8_reg";
		sd_vcc_reg = "/sd_vcc_reg";
		vdd_3v3_reg = "/fixedregulator_3v3";
		vdd_5v0_reg = "/fixedregulator_5v0";
	};
};
